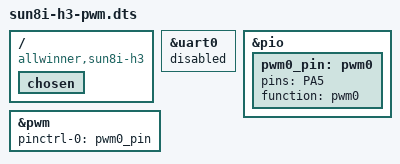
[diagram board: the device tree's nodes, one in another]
/dts-v1/;
/plugin/;

/ {
	compatible = "allwinner,sun8i-h3";

	chosen {
		/delete-property/ stdout-path;
	};
};

&uart0 {
	status = "disabled";
};

&pio {
	pwm0_pin: pwm0 {
		pins = "PA5";
		function = "pwm0";
	};
};

&pwm {
	pinctrl-names = "default";
	pinctrl-0 = <&pwm0_pin>;
	status = "okay";
};
